# m52363b register map
Vendor: Elmos Semiconductor SE; Series: Integrated Driver; File version: 1.0
CPU: CM23 r1p0, little endian, MPU, no FPU, VTOR, 2 interrupt priority bits, 13 interrupts
Registers are 16-bit, read-write, reset 0x0 unless marked. A register's access mark holds for its fields unless they carry their own. Offsets are from the block's base; [hi:lo] are bit positions; {n}, {i} and the like mark numbered series.

## CRC16 — General purpose CCITT-CRC-16 module
Base 0x40000200
0x00 START0
  [15:0] addr — addr bitfield
0x02 START1
  [15:0] addr — addr bitfield
0x04 LENGTH
  [15:0] bytes — bytes bitfield
0x08 EXPECTED_CRC
  [15:0] crc — crc bitfield
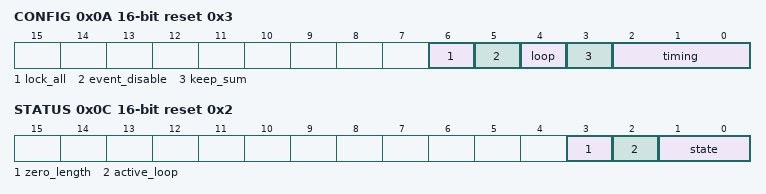
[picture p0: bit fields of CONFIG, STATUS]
0x0A CONFIG reset 0x3
  [6] lock_all — lock_all bitfield
  [5] event_disable — event_disable bitfield
  [4] loop — loop bitfield
  [3] keep_sum — keep_sum bitfield
  [2:0] timing — timing bitfield
0x0C STATUS ro reset 0x2
  [3] zero_length — zero_length bitfield
  [2] active_loop — active_loop bitfield
  [1:0] state — state bitfield
0x0E CRC_SUM reset 0xFFFF
  [15:0] crc — crc bitfield
0x10 STOP wo reset not defined
  [0] cmd — cmd bitfield
0x18 CURRENT_ADDR0 ro
  [15:0] addr — addr bitfield
0x1A CURRENT_ADDR1 ro
  [15:0] addr — addr bitfield
0x1C CURRENT_LENGTH ro
  [15:0] bytes — bytes bitfield
0x20 VERSION ro reset 0x3
  [15:0] version — version bitfield

## SFL_CTRL — Flash control module
Base 0x40000300
0x00 VERSION ro reset 0x9
  [15:0] version — version bitfield
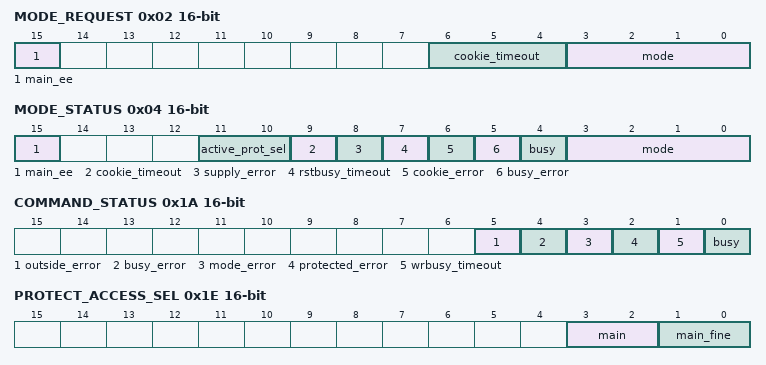
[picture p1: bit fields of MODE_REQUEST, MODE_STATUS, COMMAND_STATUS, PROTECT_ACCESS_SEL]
0x02 MODE_REQUEST
  [15] main_ee — main_ee bitfield
  [6:4] cookie_timeout — cookie_timeout bitfield
  [3:0] mode — mode bitfield
0x04 MODE_STATUS ro
  [15] main_ee — main_ee bitfield
  [11:10] active_prot_sel — active_prot_sel bitfield
  [9] cookie_timeout — cookie_timeout bitfield
  [8] supply_error — supply_error bitfield
  [7] rstbusy_timeout — rstbusy_timeout bitfield
  [6] cookie_error — cookie_error bitfield
  [5] busy_error — busy_error bitfield
  [4] busy — busy bitfield
  [3:0] mode — mode bitfield
0x06 COOKIE wo reset not defined
  [15:0] val — val bitfield
0x10 WADDR_L
  [15:0] addr — addr bitfield
0x12 WADDR_H
  [3:0] addr — addr bitfield
0x14 WDATA_L reset 0xFFFF
  [15:0] data — data bitfield
0x16 WDATA_H reset 0xFFFF
  [15:0] data — data bitfield
0x18 COMMAND wo reset not defined
  [0] run — run bitfield
0x1A COMMAND_STATUS ro
  [5] outside_error — outside_error bitfield
  [4] busy_error — busy_error bitfield
  [3] mode_error — mode_error bitfield
  [2] protected_error — protected_error bitfield
  [1] wrbusy_timeout — wrbusy_timeout bitfield
  [0] busy — busy bitfield
0x1C BUSY_MEASUREMENT ro
  [15:0] length — length bitfield
0x1E PROTECT_ACCESS_SEL
  [3:2] main — main bitfield
  [1:0] main_fine — main_fine bitfield
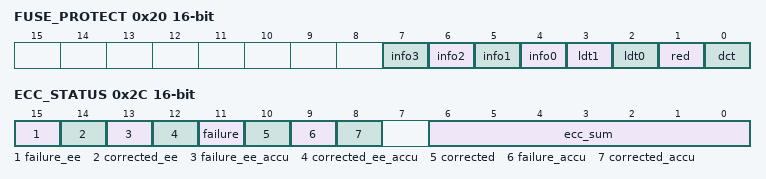
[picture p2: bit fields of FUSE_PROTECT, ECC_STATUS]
0x20 FUSE_PROTECT
  [n+4] info{n} (n=0..3) — info{n} bitfield
  [3] ldt1 — ldt1 bitfield
  [2] ldt0 — ldt0 bitfield
  [1] red — red bitfield
  [0] dct — dct bitfield
0x24 MAIN_PROTECT
  [15:0] lock — lock bitfield
0x28 MAIN_FINE_PROTECT
  [15:0] lock — lock bitfield
0x2A ECC_CONTROL
  [0] swap_bus — swap_bus bitfield
0x2C ECC_STATUS
  [15] failure_ee ro — failure_ee bitfield
  [14] corrected_ee ro — corrected_ee bitfield
  [13] failure_ee_accu — failure_ee_accu bitfield
  [12] corrected_ee_accu — corrected_ee_accu bitfield
  [11] failure ro — failure bitfield
  [10] corrected ro — corrected bitfield
  [9] failure_accu — failure_accu bitfield
  [8] corrected_accu — corrected_accu bitfield
  [6:0] ecc_sum ro — ecc_sum bitfield

## CLOCK_CTRL — Clock control module
Base 0x40000600
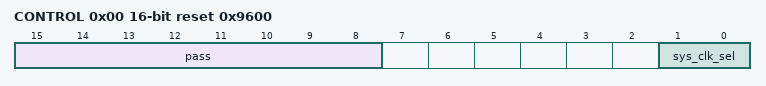
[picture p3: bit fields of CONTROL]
0x00 CONTROL reset 0x9600
  [15:8] pass — pass bitfield
  [1:0] sys_clk_sel — sys_clk_sel bitfield
0x04 STATUS ro
  [0] bus_clk_thd_enabled — bus_clk_thd_enabled bitfield
0x10 WDOG_CLK_FREQ
  [11:0] freq — freq bitfield
0x12 BUS_CLK_MEAS ro
  [10:0] cycles — cycles bitfield
0x14 BUS_CLK_MIN
  [10:0] thd — thd bitfield
0x16 BUS_CLK_MAX reset 0x7FF
  [10:0] thd — thd bitfield
0x18 COOKIE_BUS_CLK_THD wo reset not defined
  [15:0] val — val bitfield

## TIMER0 — Optional timer module
Base 0x41000000
Same registers: TIMER1 0x41000100
0x00 RELOAD 32-bit
  [23:0] val — val bitfield
0x04 COUNTER 32-bit ro
  [23:0] val — val bitfield
